# R7FA6T2BD register map
Vendor: Renesas Electronics Corporation; Series: RA6; File version: 1.40.00
CPU: CM33 r0p4, little endian, MPU, FPU, VTOR, 4 interrupt priority bits, 96 interrupts
Registers are 32-bit, read-write, reset 0x0 unless marked. A register's access mark holds for its fields unless they carry their own. Offsets are from the block's base; [hi:lo] are bit positions; {n}, {i} and the like mark numbered series.

## DAC120 — 12-bit D/A converter 0
Base 0x40172000
Same registers: DAC121 0x40172100
{0x0+2i} DADR{i} (i=0..1) 16-bit — D/A Data Register {i}
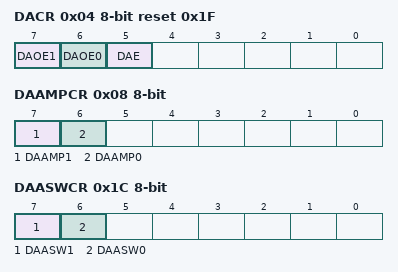
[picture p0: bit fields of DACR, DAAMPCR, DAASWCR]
0x04 DACR 8-bit reset 0x1F — D/A Control Register
  [7] DAOE1 — D/A Output Enable 1
  [6] DAOE0 — D/A Output Enable 0
  [5] DAE — D/A Enable
0x05 DADPR 8-bit — DADRn Format Select Register
  [7] DPSEL — DADRn Format Select
0x08 DAAMPCR 8-bit — D/A Output Amplifier Control Register
  [7] DAAMP1 — Amplifier Control 1
  [6] DAAMP0 — Amplifier Control 0
0x1C DAASWCR 8-bit — D/A Amplifier Stabilization Wait Control Register
  [7] DAASW1 — D/A Amplifier Stabilization Wait 1 and D/A internal output control
  [6] DAASW0 — D/A Amplifier Stabilization Wait 0 and D/A internal output control

## TSD — Temperature Sensor Calibration Data
Base 0x407FB000
0x17C TSCDR ro (reset mask 0xFFFF0000) — Temperature Sensor Calibration Data Register
  [15:0] TSCDR — Temperature Sensor Calibration Data

## FLAD — Data Flash
Base 0x407FC000
0x40 FCKMHZ 8-bit reset 0x3C — Data Flash Access Frequency Register

## FACI — Flash Application Command Interface
Base 0x407FE000
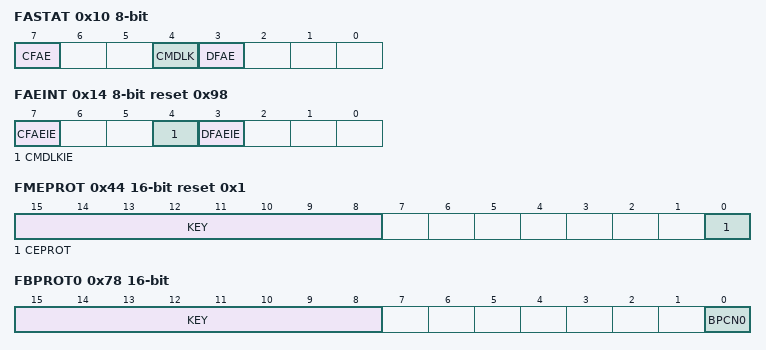
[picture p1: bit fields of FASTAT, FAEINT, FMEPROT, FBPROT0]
0x10 FASTAT 8-bit — Flash Access Status Register
  [7] CFAE — Code Flash Memory Access Violation Flag
  [4] CMDLK ro — Command Lock Flag
  [3] DFAE — Data Flash Memory Access Violation Flag
0x14 FAEINT 8-bit reset 0x98 — Flash Access Error Interrupt Enable Register
  [7] CFAEIE — Code Flash Memory Access Violation Interrupt Enable
  [4] CMDLKIE — Command Lock Interrupt Enable
  [3] DFAEIE — Data Flash Memory Access Violation Interrupt Enable
0x18 FRDYIE 8-bit — Flash Ready Interrupt Enable Register
  [0] FRDYIE — Flash Ready Interrupt Enable
0x30 FSADDR — FACI Command Start Address Register
0x34 FEADDR — FACI Command End Address Register
  [31:0] FEADDR — End Address for FACI Command Processing
0x44 FMEPROT 16-bit reset 0x1 — Flash P/E Mode Entry Protection Register
  [15:8] KEY wo — Key Code
  [0] CEPROT — Code Flash P/E Mode Entry Protection
0x78 FBPROT0 16-bit — Flash Block Protection Register
  [15:8] KEY wo — Key Code
  [0] BPCN0 — Block Protection for Non,secure Cancel
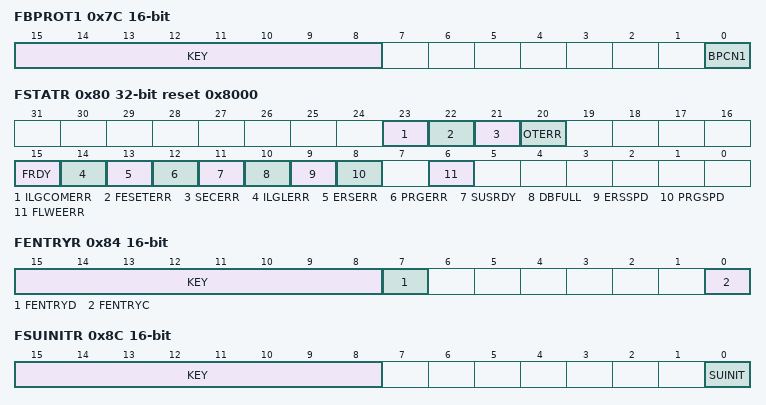
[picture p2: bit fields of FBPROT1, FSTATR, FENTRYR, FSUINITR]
0x7C FBPROT1 16-bit — Flash Block Protection for Secure Register
  [15:8] KEY wo — Key Code
  [0] BPCN1 — Block Protection for Secure Cancel
0x80 FSTATR reset 0x8000 — Flash Status Register
  [23] ILGCOMERR ro — Illegal Command Error
  [22] FESETERR ro — FENTRY Setting Error
  [21] SECERR ro — Security Error
  [20] OTERR ro — Other Error
  [15] FRDY ro — Flash Ready Flag
  [14] ILGLERR ro — Illegal Command Error Flag
  [13] ERSERR ro — Erasure Error Flag
  [12] PRGERR ro — Programming Error Flag
  [11] SUSRDY ro — Suspend Ready Flag
  [10] DBFULL ro — Data Buffer Full Flag
  [9] ERSSPD ro — Erasure Suspend Status Flag
  [8] PRGSPD ro — Programming Suspend Status Flag
  [6] FLWEERR ro — Flash Write/Erase Protect Error Flag
0x84 FENTRYR 16-bit — Flash P/E Mode Entry Register
  [15:8] KEY wo — Key Code
  [7] FENTRYD — Data Flash P/E Mode Entry
  [0] FENTRYC — Code Flash P/E Mode Entry
0x8C FSUINITR 16-bit — Flash Sequencer Setup Initialization Register
  [15:8] KEY wo — Key Code
  [0] SUINIT — Set,Up Initialization
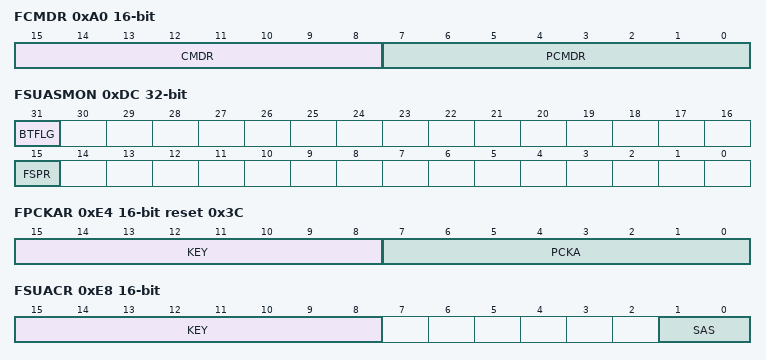
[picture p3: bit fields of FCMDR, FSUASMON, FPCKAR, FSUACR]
0xA0 FCMDR 16-bit ro — FACI Command Register
  [15:8] CMDR — Command Flag
  [7:0] PCMDR — Pre,command Flag
0xD0 FBCCNT 8-bit — Blank Check Control Register
  [0] BCDIR — Blank Check Direction
0xD4 FBCSTAT 8-bit — Blank Check Status Register
  [0] BCST ro — Blank Check Status Flag
0xD8 FPSADDR — Data Flash Programming Start Address Register
  [16:0] PSADR ro — Programmed Area Start Address
0xDC FSUASMON ro (reset mask 0x7FFF7FFF) — Flash Startup Area Select Monitor Register
  [31] BTFLG — Flag of Startup Area Select for Boot Swap
  [15] FSPR — Protection Programming Flag to set Boot Flag and Startup Area Control
0xE0 FCPSR 16-bit — Flash Sequencer Processing Switching Register
  [0] ESUSPMD — Erasure Suspend Mode
0xE4 FPCKAR 16-bit reset 0x3C — Flash Sequencer Processing Clock Notification Register
  [15:8] KEY wo — Key Code
  [7:0] PCKA — Flash Sequencer Operating Clock Notification
0xE8 FSUACR 16-bit — Flash Startup Area Control Register
  [15:8] KEY wo — Key Code
  [1:0] SAS — Startup Area Select
